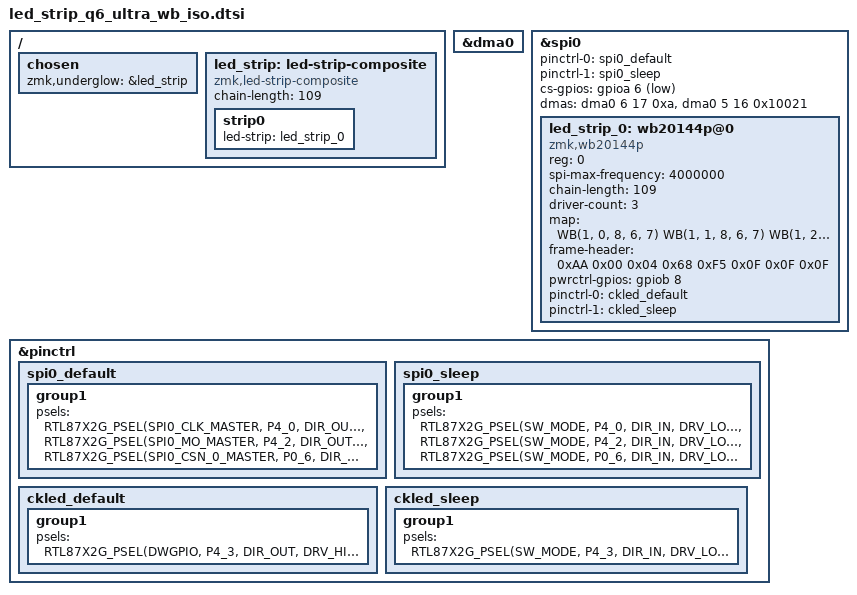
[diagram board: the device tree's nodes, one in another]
#include <dt-bindings/zmk/wb20144p.h>

/ {
    chosen {
        
        zmk,underglow = &led_strip;
    };
    led_strip: led-strip-composite {
        compatible = "zmk,led-strip-composite";
        chain-length = <109>;
        //wb20144p仅需要一根线
        strip0 {
            led-strip = <&led_strip_0>;
        };
    };

    

};
// dma is optional
&dma0 {
    status = "okay";
};
 
&spi0 {
    status = "okay";
    pinctrl-0 = <&spi0_default>;
    pinctrl-1 = <&spi0_sleep>;
    pinctrl-names = "default","sleep";
    cs-gpios=
        <&gpioa  6 GPIO_ACTIVE_LOW>;  // cs0 p0_6
        
    // dma is optional
	dmas = <&dma0 6 17 0xa>, <&dma0 5 16 0x10021>;
	dma-names = "rx", "tx";

        led_strip_0: wb20144p@0 {
            compatible = "zmk,wb20144p";
            reg = <0>;
            spi-max-frequency = <4000000>;
            chain-length = <109>; 
            driver-count = <3>; //3个驱动器
            map = <
            /* ROW 0 */
            /*   R        G        B */
            WB(1, 0, 8, 6, 7)
            WB(1, 1, 8, 6, 7)
            WB(1, 2, 8, 6, 7)
            WB(1, 3, 8, 6, 7)
            WB(1, 4, 8, 6, 7)
            WB(1, 5, 8, 6, 7)
            WB(1, 6, 8, 6, 7)
            WB(1, 7, 8, 6, 7)
            WB(1, 8, 8, 6, 7)
            WB(1, 9, 8, 6, 7)
            WB(1, 10, 8, 6, 7)
            WB(1, 11, 8, 6, 7)
            WB(1, 12, 8, 6, 7)
            WB(1, 13, 8, 6, 7)
            WB(1, 14, 8, 6, 7)
            WB(1, 15, 8, 6, 7) 

            WB(0, 1, 8, 6, 7)
            WB(0, 2, 8, 6, 7)
            WB(0, 3, 8, 6, 7)
            WB(0, 4, 8, 6, 7)       /*19*/
            

            /* ROW 1 */
            /*   R        G        B */
            WB(1, 0, 2, 0, 1)
            WB(1, 1, 2, 0, 1)
            WB(1, 2, 2, 0, 1)
            WB(1, 3, 2, 0, 1)
            WB(1, 4, 2, 0, 1)
            WB(1, 5, 2, 0, 1) 
            WB(1, 6, 2, 0, 1)
            WB(1, 7, 2, 0, 1)
            WB(1, 8, 2, 0, 1)
            WB(1, 9, 2, 0, 1)
            WB(1, 10, 2, 0, 1)
            WB(1, 11, 2, 0, 1)
            WB(1, 12, 2, 0, 1)
            WB(1, 13, 2, 0, 1)
            WB(1, 14, 2, 0, 1)
            WB(1, 15, 2, 0, 1) 

            WB(0, 0, 5, 3, 4)
            WB(0, 1, 5, 3, 4)
            WB(0, 2, 5, 3, 4)
            WB(0, 3, 5, 3, 4)
            WB(0, 4, 5, 3, 4)        /*40*/

            /* ROW 2 */
            /*   R        G        B */
            WB(1, 0, 5, 3, 4)
            WB(1, 1, 5, 3, 4)
            WB(1, 2, 5, 3, 4)
            WB(1, 3, 5, 3, 4)
            WB(1, 4, 5, 3, 4)
            WB(1, 5, 5, 3, 4)
            WB(1, 6, 5, 3, 4)
            WB(1, 7, 5, 3, 4)
            WB(1, 8, 5, 3, 4)
            WB(1, 9, 5, 3, 4)
            WB(1, 10, 5, 3, 4)
            WB(1, 11, 5, 3, 4)
            WB(1, 12, 5, 3, 4)
            WB(1, 13, 5, 3, 4)
            WB(1, 14, 5, 3, 4)
            WB(1, 15, 5, 3, 4)

            WB(0, 0, 2, 0, 1)
            WB(0, 1, 2, 0, 1)
            WB(0, 2, 2, 0, 1)
            WB(0, 3, 2, 0, 1)            

            /* ROW 3 */
            /*  R    G    B */
            WB(2, 0, 8, 6, 7)
            WB(2, 1, 8, 6, 7)
            WB(2, 2, 8, 6, 7)
            WB(2, 3, 8, 6, 7)
            WB(2, 4, 8, 6, 7)
            WB(2, 5, 8, 6, 7)
            WB(2, 6, 8, 6, 7)
            WB(2, 7, 8, 6, 7)
            WB(2, 8, 8, 6, 7)
            WB(2, 9, 8, 6, 7)
            WB(2, 10, 8, 6, 7)
            WB(2, 11, 8, 6, 7)
            WB(2, 12, 8, 6, 7)


            WB(0, 8, 8, 6, 7)
            WB(0, 7, 8, 6, 7)
            WB(0, 6, 8, 6, 7)
            WB(0, 5, 8, 6, 7)

            /* ROW 4 */
            /*   R        G        B */
            WB(2, 0, 5, 3, 4)
            WB(2, 1, 5, 3, 4)
            WB(2, 2, 5, 3, 4)
            WB(2, 3, 5, 3, 4)
            WB(2, 4, 5, 3, 4)
            WB(2, 5, 5, 3, 4)
            WB(2, 6, 5, 3, 4)
            WB(2, 7, 5, 3, 4)
            WB(2, 8, 5, 3, 4)
            WB(2, 9, 5, 3, 4)
            WB(2, 10, 5, 3, 4)
            WB(2, 11, 5, 3, 4)
            WB(2, 12, 5, 3, 4)
            WB(2, 15, 5, 3, 4)
            
            WB(0, 8, 5, 3, 4)
            WB(0, 7, 5, 3, 4)
            WB(0, 6, 5, 3, 4)

            /* ROW 5 */
            /*   R        G        B */
            WB(2, 0, 2, 0, 1)
            WB(2, 1, 2, 0, 1)
            WB(2, 2, 2, 0, 1)
            WB(2, 6, 2, 0, 1)
            WB(2, 10, 2, 0, 1)
            WB(2, 11, 2, 0, 1)
            WB(2, 12, 2, 0, 1)
            WB(2, 13, 2, 0, 1)
            WB(2, 14, 2, 0, 1)
            WB(2, 15, 2, 0, 1)      

            WB(0, 9, 2, 0, 1)
            WB(0, 8, 2, 0, 1)
            WB(0, 6, 2, 0, 1)
            WB(0, 5, 2, 0, 1)
            >;
            frame-header = <0xAA 0x00 0x04 0x68 0xF5 0x0F 0x0F 0x0F>;
            pwrctrl-gpios =<&gpiob 8 GPIO_ACTIVE_HIGH>;  //P4_3
            pinctrl-0 = <&ckled_default>;
            pinctrl-1 = <&ckled_sleep>;
            pinctrl-names = "default","sleep";
    };

};

&pinctrl {


    spi0_default:spi0_default{
        group1 {
            psels = <RTL87X2G_PSEL(SPI0_CLK_MASTER, P4_0, DIR_OUT, DRV_HIGH, PULL_UP)>,
            <RTL87X2G_PSEL(SPI0_MO_MASTER, P4_2, DIR_OUT, DRV_HIGH, PULL_UP)>,
            <RTL87X2G_PSEL(SPI0_CSN_0_MASTER, P0_6, DIR_OUT, DRV_HIGH, PULL_UP)>;
        };
    };
    spi0_sleep:spi0_sleep{
        group1 {
            psels = <RTL87X2G_PSEL(SW_MODE, P4_0, DIR_IN, DRV_LOW, PULL_DOWN)>,
            <RTL87X2G_PSEL(SW_MODE, P4_2, DIR_IN, DRV_LOW, PULL_DOWN)>,
            <RTL87X2G_PSEL(SW_MODE, P0_6, DIR_IN, DRV_LOW, PULL_DOWN)>;
        };
    };
    ckled_default:ckled_default {
        group1 {
            psels =
            <RTL87X2G_PSEL(DWGPIO, P4_3, DIR_OUT, DRV_HIGH, PULL_UP)>;
            
        };
    };
    ckled_sleep:ckled_sleep {
        group1 {
            psels =
            <RTL87X2G_PSEL(SW_MODE, P4_3, DIR_IN, DRV_LOW, PULL_DOWN)>;
            
        };
    };
};
